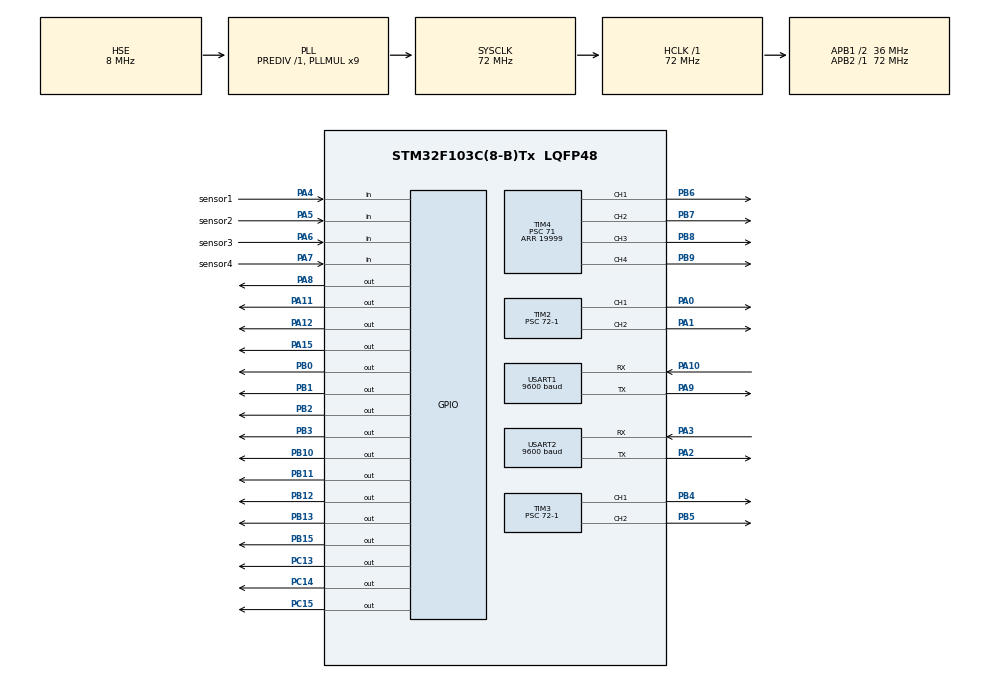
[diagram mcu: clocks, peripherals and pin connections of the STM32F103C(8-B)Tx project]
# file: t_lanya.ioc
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Dma.Request0=USART1_RX
Dma.Request1=USART1_TX
Dma.Request2=USART2_RX
Dma.Request3=USART2_TX
Dma.Request4=TIM4_CH1
Dma.TIM4_CH1.4.Direction=DMA_PERIPH_TO_MEMORY
Dma.TIM4_CH1.4.Instance=DMA1_Channel1
Dma.TIM4_CH1.4.MemDataAlignment=DMA_MDATAALIGN_HALFWORD
Dma.TIM4_CH1.4.MemInc=DMA_MINC_ENABLE
Dma.TIM4_CH1.4.Mode=DMA_NORMAL
Dma.TIM4_CH1.4.PeriphDataAlignment=DMA_PDATAALIGN_HALFWORD
Dma.TIM4_CH1.4.PeriphInc=DMA_PINC_DISABLE
Dma.TIM4_CH1.4.Priority=DMA_PRIORITY_LOW
Dma.USART1_RX.0.Direction=DMA_PERIPH_TO_MEMORY
Dma.USART1_RX.0.Instance=DMA1_Channel5
Dma.USART1_RX.0.MemDataAlignment=DMA_MDATAALIGN_BYTE
Dma.USART1_RX.0.MemInc=DMA_MINC_ENABLE
Dma.USART1_RX.0.Mode=DMA_NORMAL
Dma.USART1_RX.0.PeriphDataAlignment=DMA_PDATAALIGN_BYTE
Dma.USART1_RX.0.PeriphInc=DMA_PINC_DISABLE
Dma.USART1_RX.0.Priority=DMA_PRIORITY_LOW
Dma.USART1_TX.1.Direction=DMA_MEMORY_TO_PERIPH
Dma.USART1_TX.1.Instance=DMA1_Channel4
Dma.USART1_TX.1.MemDataAlignment=DMA_MDATAALIGN_BYTE
Dma.USART1_TX.1.MemInc=DMA_MINC_ENABLE
Dma.USART1_TX.1.Mode=DMA_NORMAL
Dma.USART1_TX.1.PeriphDataAlignment=DMA_PDATAALIGN_BYTE
Dma.USART1_TX.1.PeriphInc=DMA_PINC_DISABLE
Dma.USART1_TX.1.Priority=DMA_PRIORITY_LOW
Dma.USART2_RX.2.Direction=DMA_PERIPH_TO_MEMORY
Dma.USART2_RX.2.Instance=DMA1_Channel6
Dma.USART2_RX.2.MemDataAlignment=DMA_MDATAALIGN_BYTE
Dma.USART2_RX.2.MemInc=DMA_MINC_ENABLE
Dma.USART2_RX.2.Mode=DMA_NORMAL
Dma.USART2_RX.2.PeriphDataAlignment=DMA_PDATAALIGN_BYTE
Dma.USART2_RX.2.PeriphInc=DMA_PINC_DISABLE
Dma.USART2_RX.2.Priority=DMA_PRIORITY_LOW
Dma.USART2_TX.3.Direction=DMA_MEMORY_TO_PERIPH
Dma.USART2_TX.3.Instance=DMA1_Channel7
Dma.USART2_TX.3.MemDataAlignment=DMA_MDATAALIGN_BYTE
Dma.USART2_TX.3.MemInc=DMA_MINC_ENABLE
Dma.USART2_TX.3.Mode=DMA_NORMAL
Dma.USART2_TX.3.PeriphDataAlignment=DMA_PDATAALIGN_BYTE
Dma.USART2_TX.3.PeriphInc=DMA_PINC_DISABLE
Dma.USART2_TX.3.Priority=DMA_PRIORITY_LOW
Mcu.Family=STM32F1
Mcu.Name=STM32F103C(8-B)Tx
Mcu.Package=LQFP48
NVIC.DMA1_Channel1_IRQn=true\:0\:0\:false\:false\:true\:false\:true\:true
NVIC.DMA1_Channel4_IRQn=true\:0\:0\:false\:false\:true\:false\:true\:true
NVIC.DMA1_Channel5_IRQn=true\:0\:0\:false\:false\:true\:false\:true\:true
NVIC.DMA1_Channel6_IRQn=true\:0\:0\:false\:false\:true\:false\:true\:true
NVIC.DMA1_Channel7_IRQn=true\:0\:0\:false\:false\:true\:false\:true\:true
NVIC.PriorityGroup=NVIC_PRIORITYGROUP_4
NVIC.USART1_IRQn=true\:0\:0\:false\:false\:true\:true\:true\:true
NVIC.USART2_IRQn=true\:0\:0\:false\:false\:true\:true\:true\:true
PA0-WKUP.Signal=S_TIM2_CH1_ETR
PA1.Signal=S_TIM2_CH2
PA10.Mode=Asynchronous
PA10.Signal=USART1_RX
PA11.Signal=GPIO_Output
PA12.Signal=GPIO_Output
PA13.Mode=Serial_Wire
PA13.Signal=SYS_JTMS-SWDIO
PA14.Mode=Serial_Wire
PA14.Signal=SYS_JTCK-SWCLK
PA15.Signal=GPIO_Output
PA2.Mode=Asynchronous
PA2.Signal=USART2_TX
PA3.Mode=Asynchronous
PA3.Signal=USART2_RX
PA4.GPIO_Label=sensor1
PA4.Signal=GPIO_Input
PA5.GPIO_Label=sensor2
PA5.Signal=GPIO_Input
PA6.GPIO_Label=sensor3
PA6.Signal=GPIO_Input
PA7.GPIO_Label=sensor4
PA7.Signal=GPIO_Input
PA8.Signal=GPIO_Output
PA9.Mode=Asynchronous
PA9.Signal=USART1_TX
PB0.Signal=GPIO_Output
PB1.Signal=GPIO_Output
PB10.Signal=GPIO_Output
PB11.Signal=GPIO_Output
PB12.Signal=GPIO_Output
PB13.Signal=GPIO_Output
PB15.Signal=GPIO_Output
PB2.Signal=GPIO_Output
PB3.Signal=GPIO_Output
PB4.Signal=S_TIM3_CH1
PB5.Signal=S_TIM3_CH2
PB6.Signal=S_TIM4_CH1
PB7.Signal=S_TIM4_CH2
PB8.Signal=S_TIM4_CH3
PB9.Signal=S_TIM4_CH4
PC13-TAMPER-RTC.Signal=GPIO_Output
PC14-OSC32_IN.Signal=GPIO_Output
PC15-OSC32_OUT.Signal=GPIO_Output
PD0-OSC_IN.Mode=HSE-External-Oscillator
PD0-OSC_IN.Signal=RCC_OSC_IN
PD1-OSC_OUT.Mode=HSE-External-Oscillator
PD1-OSC_OUT.Signal=RCC_OSC_OUT
ProjectManager.HeapSize=0x200
ProjectManager.StackSize=0x400
ProjectManager.TargetToolchain=MDK-ARM V5.32
RCC.AHBFreq_Value=72000000
RCC.APB1CLKDivider=RCC_HCLK_DIV2
RCC.APB1Freq_Value=36000000
RCC.APB1TimFreq_Value=72000000
RCC.APB2Freq_Value=72000000
RCC.APB2TimFreq_Value=72000000
RCC.HCLKFreq_Value=72000000
RCC.PLLMUL=RCC_PLL_MUL9
RCC.PLLSourceVirtual=RCC_PLLSOURCE_HSE
RCC.SYSCLKFreq_VALUE=72000000
RCC.SYSCLKSource=RCC_SYSCLKSOURCE_PLLCLK
RCC.USBFreq_Value=72000000
SH.S_TIM2_CH1_ETR.0=TIM2_CH1,PWM Generation1 CH1
SH.S_TIM2_CH2.0=TIM2_CH2,PWM Generation2 CH2
SH.S_TIM3_CH1.0=TIM3_CH1,PWM Generation1 CH1
SH.S_TIM3_CH2.0=TIM3_CH2,PWM Generation2 CH2
SH.S_TIM4_CH1.0=TIM4_CH1,PWM Generation1 CH1
SH.S_TIM4_CH2.0=TIM4_CH2,PWM Generation2 CH2
SH.S_TIM4_CH3.0=TIM4_CH3,PWM Generation3 CH3
SH.S_TIM4_CH4.0=TIM4_CH4,PWM Generation4 CH4
TIM2.Channel-PWM\ Generation1\ CH1=TIM_CHANNEL_1
TIM2.Channel-PWM\ Generation2\ CH2=TIM_CHANNEL_2
TIM2.Prescaler=72-1
TIM3.Channel-PWM\ Generation1\ CH1=TIM_CHANNEL_1
TIM3.Channel-PWM\ Generation2\ CH2=TIM_CHANNEL_2
TIM3.Prescaler=72-1
TIM4.AutoReloadPreload=TIM_AUTORELOAD_PRELOAD_ENABLE
TIM4.Channel-PWM\ Generation1\ CH1=TIM_CHANNEL_1
TIM4.Channel-PWM\ Generation2\ CH2=TIM_CHANNEL_2
TIM4.Channel-PWM\ Generation3\ CH3=TIM_CHANNEL_3
TIM4.Channel-PWM\ Generation4\ CH4=TIM_CHANNEL_4
TIM4.OCPolarity_1=TIM_OCPOLARITY_HIGH
TIM4.OCPolarity_2=TIM_OCPOLARITY_HIGH
TIM4.OCPolarity_3=TIM_OCPOLARITY_HIGH
TIM4.OCPolarity_4=TIM_OCPOLARITY_HIGH
TIM4.Period=19999
TIM4.Prescaler=71
USART1.BaudRate=9600
USART1.VirtualMode=VM_ASYNC
USART2.BaudRate=9600
USART2.VirtualMode=VM_ASYNC
VP_TIM2_VS_ClockSourceINT.Mode=Internal
VP_TIM3_VS_ClockSourceINT.Mode=Internal
VP_TIM4_VS_ClockSourceINT.Mode=Internal
board=custom

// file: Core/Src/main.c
/* USER CODE BEGIN Header */
/**
  ******************************************************************************
  * @file           : main.c
  * @brief          : Main program body
  ******************************************************************************
  * @attention
  *
  * Copyright (c) 2025 STMicroelectronics.
  * All rights reserved.
  *
  * This software is licensed under terms that can be found in the LICENSE file
  * in the root directory of this software component.
  * If no LICENSE file comes with this software, it is provided AS-IS.
  *
  ******************************************************************************
  */
/* USER CODE END Header */
#include "main.h"
#include "dma.h"
#include "tim.h"
#include "usart.h"
#include "gpio.h"

/* USER CODE BEGIN Includes */
#include "globalvars.h"
#include "servo.h"
#include "Bluetooth.h"
#include <string.h>
#include "track.h"
#include "motor.h"
/* USER CODE END Includes */

void SystemClock_Config(void);

int main(void)
{

  /* MCU Configuration--------------------------------------------------------*/

  /* Reset of all peripherals, Initializes the Flash interface and the Systick. */
  HAL_Init();

  /* Configure the system clock */
  SystemClock_Config();

  /* Initialize all configured peripherals */
  MX_GPIO_Init();
  MX_DMA_Init();
  MX_USART1_UART_Init();
  MX_USART2_UART_Init();
  MX_TIM4_Init();
  MX_TIM2_Init();
  MX_TIM3_Init();
  /* USER CODE BEGIN 2 */
	GlobalVars_Init();       // 初始化全局变量（舵机状态、红外模式等）
  Servo_Init();            // 舵机初始化（启动PWM，复位机械臂）
//  Motor_Init();            // 电机初始化（启动PWM，停止状态）
	Bluetooth_Init();        // 蓝牙初始化（启动中断接收）
//--------------------------  --------------------------
  /* USER CODE END 2 */

  /* Infinite loop */
  /* USER CODE BEGIN WHILE */
  while (1)
  {

////__HAL_TIM_SET_COMPARE(&htim2,TIM_CHANNEL_1,1000);//电机1（TIM2_CH1)
//		HAL_GPIO_WritePin(MOTOR1_IN1_Port,MOTOR1_IN1_Pin,GPIO_PIN_SET);
//	HAL_GPIO_WritePin(MOTOR1_IN2_Port,MOTOR1_IN2_Pin,GPIO_PIN_RESET);

	//设置速度

		Tracking();

    /* USER CODE END WHILE */

  }
}

void SystemClock_Config(void)
{
  RCC_OscInitTypeDef RCC_OscInitStruct = {0};
  RCC_ClkInitTypeDef RCC_ClkInitStruct = {0};

  /** Initializes the RCC Oscillators according to the specified parameters
  * in the RCC_OscInitTypeDef structure.
  */
  RCC_OscInitStruct.OscillatorType = RCC_OSCILLATORTYPE_HSE;
  RCC_OscInitStruct.HSEState = RCC_HSE_ON;
  RCC_OscInitStruct.HSEPredivValue = RCC_HSE_PREDIV_DIV1;
  RCC_OscInitStruct.HSIState = RCC_HSI_ON;
  RCC_OscInitStruct.PLL.PLLState = RCC_PLL_ON;
  RCC_OscInitStruct.PLL.PLLSource = RCC_PLLSOURCE_HSE;
  RCC_OscInitStruct.PLL.PLLMUL = RCC_PLL_MUL9;
  if (HAL_RCC_OscConfig(&RCC_OscInitStruct) != HAL_OK)
  {
    Error_Handler();
  }

  /** Initializes the CPU, AHB and APB buses clocks
  */
  RCC_ClkInitStruct.ClockType = RCC_CLOCKTYPE_HCLK|RCC_CLOCKTYPE_SYSCLK
                              |RCC_CLOCKTYPE_PCLK1|RCC_CLOCKTYPE_PCLK2;
  RCC_ClkInitStruct.SYSCLKSource = RCC_SYSCLKSOURCE_PLLCLK;
  RCC_ClkInitStruct.AHBCLKDivider = RCC_SYSCLK_DIV1;
  RCC_ClkInitStruct.APB1CLKDivider = RCC_HCLK_DIV2;
  RCC_ClkInitStruct.APB2CLKDivider = RCC_HCLK_DIV1;

  if (HAL_RCC_ClockConfig(&RCC_ClkInitStruct, FLASH_LATENCY_2) != HAL_OK)
  {
    Error_Handler();
  }
}

void Error_Handler(void)
{
  __disable_irq();
  while (1)
  {
  }
}
